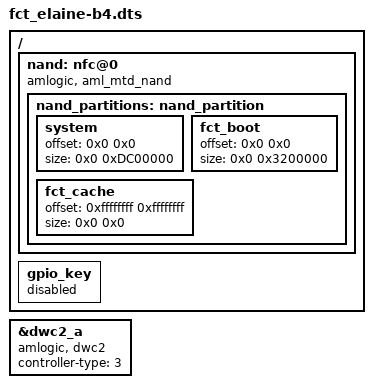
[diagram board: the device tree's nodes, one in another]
/*
 * arch/arm64/boot/dts/amlogic/fct_elaine-b4.dts
 *
 * Copyright (C) 2017 Amlogic, Inc. All rights reserved.
 *
 * This program is free software; you can redistribute it and/or modify
 * it under the terms of the GNU General Public License as published by
 * the Free Software Foundation; either version 2 of the License, or
 * (at your option) any later version.
 *
 * This program is distributed in the hope that it will be useful, but WITHOUT
 * ANY WARRANTY; without even the implied warranty of MERCHANTABILITY or
 * FITNESS FOR A PARTICULAR PURPOSE.  See the GNU General Public License for
 * more details.
 *
 */

#include "elaine-b4.dts"
/ {
	nand: nfc@0{
		compatible = "amlogic, aml_mtd_nand";
		nand_partitions:nand_partition{
			/delete-node/cache;
			system{
				offset=<0x0 0x0>;
				size=<0x0 0xDC00000>;
				/delete-property/read-only;
			};
			fct_boot{
				offset=<0x0 0x0>;
				size=<0x0 0x3200000>;
			};
			fct_cache{
				offset=<0xffffffff 0xffffffff>;
				size=<0x0 0x0>;
			};
		};
	};

	gpio_key {
		status = "disable";
	};
}; /* end of / */

&dwc2_a {
	compatible = "amlogic, dwc2";
	controller-type = <3>; /** 1: host, 2: device, 3: OTG */
};
